AUTOSAR XML (schema 4-2-1)
# Copyright (c) 2018 Vector Informatik GmbH.
# License is restricted to the usage with CBD1800851 (D01) for MSR_Ford_SLP1.
# Please contact Vector Informatik whenever you need further information concerning the license conditions.
standard types defined: boolean, sint8, uint16, uint32, uint8
package /VehicleProject
  system System
package /Cluster
  can cluster CAN00: protocol-name=CAN  # PlatformDBCE4v7
    can physical channel CHNL: comm-connectors=CN_CAN00
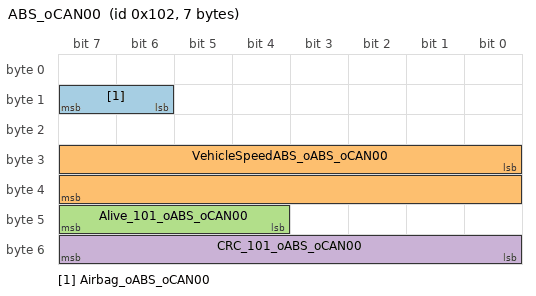
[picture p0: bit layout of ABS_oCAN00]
      frame ABS_oCAN00: id 0x102, to IC, frame-length=7, can-addressing-mode=STANDARD
        pdu ABS_oCAN00: length=7, minimum-delay=0, transmission-mode-false-timing=cyclic-timing={time-offset=0, time-period=0.1}, transmission-mode-true-timing=cyclic-timing={time-offset=0, time-period=0.1}, unused-bit-pattern=0
          signal Airbag_oABS_oCAN00: start 14, 2 bit, little-endian, init-value=0, base-type=uint8, compu {0=Cx0_Off, 1=Cx1_On, 2=Cx2_Blink, 3=Cx3_Reserved}, transfer-property=PENDING, to IC
          signal VehicleSpeedABS_oABS_oCAN00: start 24, 16 bit, little-endian, init-value=0, base-type=uint16, compu {phys=raw*0.0625 for raw 0..4800; unit kmph}, unit=kmph, transfer-property=PENDING, to IC
          signal Alive_101_oABS_oCAN00: start 44, 4 bit, little-endian, init-value=0, base-type=uint8, compu {identical}, range raw 0..15, transfer-property=PENDING, to IC
          signal CRC_101_oABS_oCAN00: start 48, 8 bit, little-endian, init-value=0, base-type=uint8, compu {identical}, range raw 0..255, transfer-property=PENDING, to IC
          mapping SG_ABS: i-signal-group=SG_ABS_oABS_oCAN00, transfer-property=PENDING
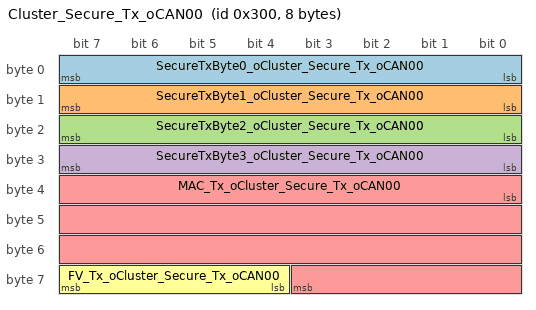
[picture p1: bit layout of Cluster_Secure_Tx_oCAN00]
      frame Cluster_Secure_Tx_oCAN00: id 0x300, from IC, frame-length=8, can-addressing-mode=STANDARD
        pdu Cluster_Secure_Tx_oCAN00: length=8, minimum-delay=0, transmission-mode-false-timing=cyclic-timing={time-offset=0, time-period=0}, transmission-mode-true-timing=cyclic-timing={time-offset=0, time-period=0}, unused-bit-pattern=0
          signal SecureTxByte0_oCluster_Secure_Tx_oCAN00: start 0, 8 bit, little-endian, init-value=0, base-type=uint8, compu {identical}, range raw 0..255, transfer-property=PENDING
          signal SecureTxByte1_oCluster_Secure_Tx_oCAN00: start 8, 8 bit, little-endian, init-value=0, base-type=uint8, compu {identical}, range raw 0..255, transfer-property=PENDING
          signal SecureTxByte2_oCluster_Secure_Tx_oCAN00: start 16, 8 bit, little-endian, init-value=0, base-type=uint8, compu {identical}, range raw 0..255, transfer-property=PENDING
          signal SecureTxByte3_oCluster_Secure_Tx_oCAN00: start 24, 8 bit, little-endian, init-value=0, base-type=uint8, compu {identical}, range raw 0..255, transfer-property=PENDING
          signal MAC_Tx_oCluster_Secure_Tx_oCAN00: start 32, 28 bit, little-endian, init-value=0, base-type=uint32, compu {identical}, range raw 0..268435455, transfer-property=PENDING  # 28 bit CMAC/HMAC for securing the message
          signal FV_Tx_oCluster_Secure_Tx_oCAN00: start 60, 4 bit, little-endian, init-value=0, base-type=uint8, compu {identical}, range raw 0..15, unit=No Unit, transfer-property=PENDING
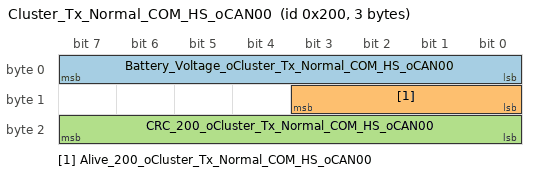
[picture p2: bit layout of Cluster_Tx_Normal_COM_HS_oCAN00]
      frame Cluster_Tx_Normal_COM_HS_oCAN00: id 0x200, from IC, frame-length=3, can-addressing-mode=STANDARD
        pdu Cluster_Tx_Normal_COM_HS_oCAN00: length=3, minimum-delay=0, transmission-mode-false-timing=cyclic-timing={time-offset=0, time-period=0.01}, transmission-mode-true-timing=cyclic-timing={time-offset=0, time-period=0.01}, unused-bit-pattern=0
          signal Battery_Voltage_oCluster_Tx_Normal_COM_HS_oCAN00: start 0, 8 bit, little-endian, init-value=0, base-type=uint8, compu {phys=raw*0.25 for raw 0..255; unit V}, unit=V, transfer-property=PENDING
          signal Alive_200_oCluster_Tx_Normal_COM_HS_oCAN00: start 8, 4 bit, little-endian, init-value=0, base-type=uint8, compu {identical}, range raw 0..15, transfer-property=PENDING
          signal CRC_200_oCluster_Tx_Normal_COM_HS_oCAN00: start 16, 8 bit, little-endian, init-value=0, base-type=uint8, compu {identical}, range raw 0..255, transfer-property=PENDING
          mapping SG_COM_HS: i-signal-group=SG_COM_HS_oCluster_Tx_Normal_COM_HS_oCAN00, transfer-property=PENDING
      frame Cluster_Tx_Normal_COM_LS_oCAN00: id 0x202, from IC, frame-length=4, can-addressing-mode=STANDARD
        pdu Cluster_Tx_Normal_COM_LS_oCAN00: length=4, minimum-delay=0, transmission-mode-false-timing=cyclic-timing={time-offset=0, time-period=1}, transmission-mode-true-timing=cyclic-timing={time-offset=0, time-period=1}, unused-bit-pattern=0
          signal Odometer_oCluster_Tx_Normal_COM_LS_oCAN00: start 0, 32 bit, little-endian, init-value=0, base-type=uint32, compu {identical}, range raw 0..1609343, unit=km, transfer-property=PENDING
      frame Cluster_Tx_Normal_COM_MS_oCAN00: id 0x201, from IC, frame-length=2, can-addressing-mode=STANDARD
        pdu Cluster_Tx_Normal_COM_MS_oCAN00: length=2, minimum-delay=0, transmission-mode-false-timing=cyclic-timing={time-offset=0, time-period=0.1}, transmission-mode-true-timing=cyclic-timing={time-offset=0, time-period=0.1}, unused-bit-pattern=0
          signal VehicleSpeedIC_oCluster_Tx_Normal_COM_MS_oCAN00: start 0, 16 bit, little-endian, init-value=0, base-type=uint16, compu {phys=raw*0.0625 for raw 0..4800; unit kmph}, unit=kmph, transfer-property=PENDING
      frame Cluster_Tx_Reduced_Com_oCAN00: id 0x210, from IC, frame-length=1, can-addressing-mode=STANDARD  # to be transmitted in reduced comm state as well
        pdu Cluster_Tx_Reduced_Com_oCAN00: length=1, minimum-delay=0, transmission-mode-false-timing=cyclic-timing={time-offset=0, time-period=0.1}, transmission-mode-true-timing=cyclic-timing={time-offset=0, time-period=0.1}, unused-bit-pattern=0
          signal Illumination_PWM_oCluster_Tx_Reduced_Com_oCAN00: start 0, 8 bit, little-endian, init-value=0, base-type=uint8, compu {identical}, range raw 0..100, unit=%, transfer-property=PENDING
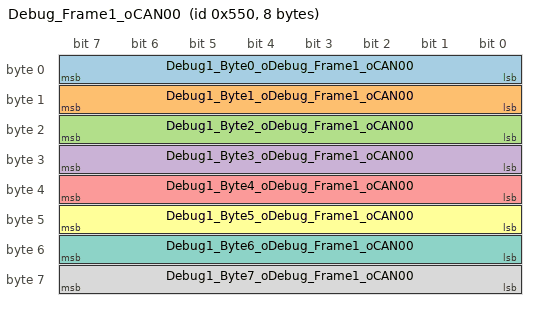
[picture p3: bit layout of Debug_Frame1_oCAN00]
      frame Debug_Frame1_oCAN00: id 0x550, from IC, frame-length=8, can-addressing-mode=STANDARD
        pdu Debug_Frame1_oCAN00: length=8, minimum-delay=0, transmission-mode-false-timing=cyclic-timing={time-offset=0, time-period=0.01}, transmission-mode-true-timing=cyclic-timing={time-offset=0, time-period=0.01}, unused-bit-pattern=0
          signal Debug1_Byte0_oDebug_Frame1_oCAN00: start 0, 8 bit, little-endian, init-value=0, base-type=uint8, compu {identical}, range raw 0..255, transfer-property=PENDING
          signal Debug1_Byte1_oDebug_Frame1_oCAN00: start 8, 8 bit, little-endian, init-value=0, base-type=uint8, compu {identical}, range raw 0..255, transfer-property=PENDING
          signal Debug1_Byte2_oDebug_Frame1_oCAN00: start 16, 8 bit, little-endian, init-value=0, base-type=uint8, compu {identical}, range raw 0..255, transfer-property=PENDING
          signal Debug1_Byte3_oDebug_Frame1_oCAN00: start 24, 8 bit, little-endian, init-value=0, base-type=uint8, compu {identical}, range raw 0..255, transfer-property=PENDING
          signal Debug1_Byte4_oDebug_Frame1_oCAN00: start 32, 8 bit, little-endian, init-value=0, base-type=uint8, compu {identical}, range raw 0..255, transfer-property=PENDING
          signal Debug1_Byte5_oDebug_Frame1_oCAN00: start 40, 8 bit, little-endian, init-value=0, base-type=uint8, compu {identical}, range raw 0..255, transfer-property=PENDING
          signal Debug1_Byte6_oDebug_Frame1_oCAN00: start 48, 8 bit, little-endian, init-value=0, base-type=uint8, compu {identical}, range raw 0..255, transfer-property=PENDING
          signal Debug1_Byte7_oDebug_Frame1_oCAN00: start 56, 8 bit, little-endian, init-value=0, base-type=uint8, compu {identical}, range raw 0..255, transfer-property=PENDING
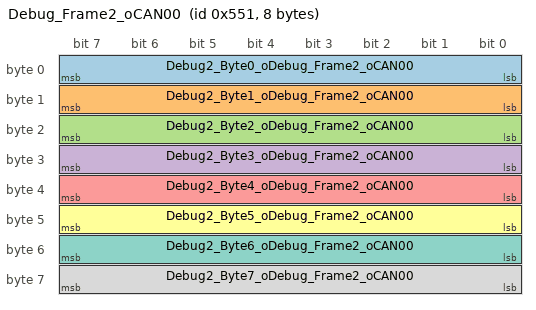
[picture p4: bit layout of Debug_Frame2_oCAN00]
      frame Debug_Frame2_oCAN00: id 0x551, from IC, frame-length=8, can-addressing-mode=STANDARD
        pdu Debug_Frame2_oCAN00: length=8, minimum-delay=0, transmission-mode-false-timing=cyclic-timing={time-offset=0, time-period=0.1}, transmission-mode-true-timing=cyclic-timing={time-offset=0, time-period=0.1}, unused-bit-pattern=0
          signal Debug2_Byte0_oDebug_Frame2_oCAN00: start 0, 8 bit, little-endian, init-value=0, base-type=uint8, compu {identical}, range raw 0..255, transfer-property=PENDING
          signal Debug2_Byte1_oDebug_Frame2_oCAN00: start 8, 8 bit, little-endian, init-value=0, base-type=uint8, compu {identical}, range raw 0..255, transfer-property=PENDING
          signal Debug2_Byte2_oDebug_Frame2_oCAN00: start 16, 8 bit, little-endian, init-value=0, base-type=uint8, compu {identical}, range raw 0..255, transfer-property=PENDING
          signal Debug2_Byte3_oDebug_Frame2_oCAN00: start 24, 8 bit, little-endian, init-value=0, base-type=uint8, compu {identical}, range raw 0..255, transfer-property=PENDING
          signal Debug2_Byte4_oDebug_Frame2_oCAN00: start 32, 8 bit, little-endian, init-value=0, base-type=uint8, compu {identical}, range raw 0..255, transfer-property=PENDING
          signal Debug2_Byte5_oDebug_Frame2_oCAN00: start 40, 8 bit, little-endian, init-value=0, base-type=uint8, compu {identical}, range raw 0..255, transfer-property=PENDING
          signal Debug2_Byte6_oDebug_Frame2_oCAN00: start 48, 8 bit, little-endian, init-value=0, base-type=uint8, compu {identical}, range raw 0..255, transfer-property=PENDING
          signal Debug2_Byte7_oDebug_Frame2_oCAN00: start 56, 8 bit, little-endian, init-value=0, base-type=uint8, compu {identical}, range raw 0..255, transfer-property=PENDING
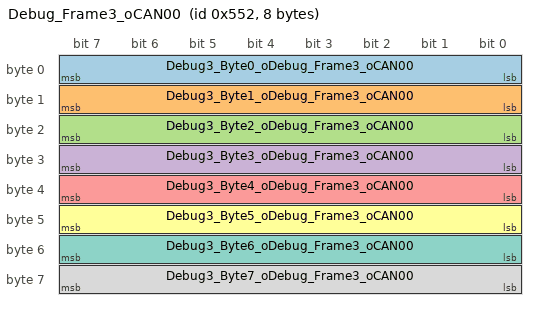
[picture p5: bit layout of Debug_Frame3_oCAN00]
      frame Debug_Frame3_oCAN00: id 0x552, from IC, frame-length=8, can-addressing-mode=STANDARD
        pdu Debug_Frame3_oCAN00: length=8, minimum-delay=0, transmission-mode-false-timing=cyclic-timing={time-offset=0, time-period=0.1}, transmission-mode-true-timing=cyclic-timing={time-offset=0, time-period=0.1}, unused-bit-pattern=0
          signal Debug3_Byte0_oDebug_Frame3_oCAN00: start 0, 8 bit, little-endian, init-value=0, base-type=uint8, compu {identical}, range raw 0..255, transfer-property=PENDING
          signal Debug3_Byte1_oDebug_Frame3_oCAN00: start 8, 8 bit, little-endian, init-value=0, base-type=uint8, compu {identical}, range raw 0..255, transfer-property=PENDING
          signal Debug3_Byte2_oDebug_Frame3_oCAN00: start 16, 8 bit, little-endian, init-value=0, base-type=uint8, compu {identical}, range raw 0..255, transfer-property=PENDING
          signal Debug3_Byte3_oDebug_Frame3_oCAN00: start 24, 8 bit, little-endian, init-value=0, base-type=uint8, compu {identical}, range raw 0..255, transfer-property=PENDING
          signal Debug3_Byte4_oDebug_Frame3_oCAN00: start 32, 8 bit, little-endian, init-value=0, base-type=uint8, compu {identical}, range raw 0..255, transfer-property=PENDING
          signal Debug3_Byte5_oDebug_Frame3_oCAN00: start 40, 8 bit, little-endian, init-value=0, base-type=uint8, compu {identical}, range raw 0..255, transfer-property=PENDING
          signal Debug3_Byte6_oDebug_Frame3_oCAN00: start 48, 8 bit, little-endian, init-value=0, base-type=uint8, compu {identical}, range raw 0..255, transfer-property=PENDING
          signal Debug3_Byte7_oDebug_Frame3_oCAN00: start 56, 8 bit, little-endian, init-value=0, base-type=uint8, compu {identical}, range raw 0..255, transfer-property=PENDING
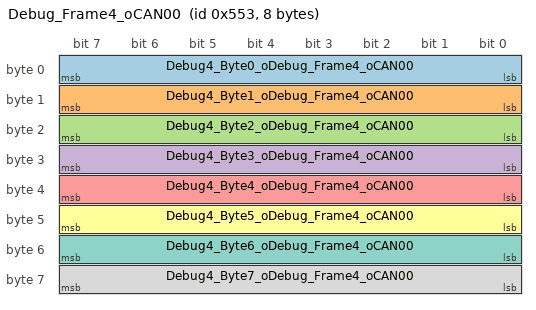
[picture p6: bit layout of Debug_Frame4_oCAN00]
      frame Debug_Frame4_oCAN00: id 0x553, from IC, frame-length=8, can-addressing-mode=STANDARD
        pdu Debug_Frame4_oCAN00: length=8, minimum-delay=0, transmission-mode-false-timing=cyclic-timing={time-offset=0, time-period=0.1}, transmission-mode-true-timing=cyclic-timing={time-offset=0, time-period=0.1}, unused-bit-pattern=0
          signal Debug4_Byte0_oDebug_Frame4_oCAN00: start 0, 8 bit, little-endian, init-value=0, base-type=uint8, compu {identical}, range raw 0..255, transfer-property=PENDING
          signal Debug4_Byte1_oDebug_Frame4_oCAN00: start 8, 8 bit, little-endian, init-value=0, base-type=uint8, compu {identical}, range raw 0..255, transfer-property=PENDING
          signal Debug4_Byte2_oDebug_Frame4_oCAN00: start 16, 8 bit, little-endian, init-value=0, base-type=uint8, compu {identical}, range raw 0..255, transfer-property=PENDING
          signal Debug4_Byte3_oDebug_Frame4_oCAN00: start 24, 8 bit, little-endian, init-value=0, base-type=uint8, compu {identical}, range raw 0..255, transfer-property=PENDING
          signal Debug4_Byte4_oDebug_Frame4_oCAN00: start 32, 8 bit, little-endian, init-value=0, base-type=uint8, compu {identical}, range raw 0..255, transfer-property=PENDING
          signal Debug4_Byte5_oDebug_Frame4_oCAN00: start 40, 8 bit, little-endian, init-value=0, base-type=uint8, compu {identical}, range raw 0..255, transfer-property=PENDING
          signal Debug4_Byte6_oDebug_Frame4_oCAN00: start 48, 8 bit, little-endian, init-value=0, base-type=uint8, compu {identical}, range raw 0..255, transfer-property=PENDING
          signal Debug4_Byte7_oDebug_Frame4_oCAN00: start 56, 8 bit, little-endian, init-value=0, base-type=uint8, compu {identical}, range raw 0..255, transfer-property=PENDING
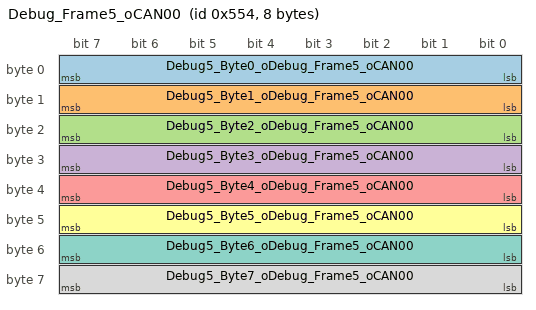
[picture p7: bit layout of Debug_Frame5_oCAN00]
      frame Debug_Frame5_oCAN00: id 0x554, from IC, frame-length=8, can-addressing-mode=STANDARD
        pdu Debug_Frame5_oCAN00: length=8, minimum-delay=0, transmission-mode-false-timing=cyclic-timing={time-offset=0, time-period=0}, transmission-mode-true-timing=cyclic-timing={time-offset=0, time-period=0}, unused-bit-pattern=0
          signal Debug5_Byte0_oDebug_Frame5_oCAN00: start 0, 8 bit, little-endian, init-value=0, base-type=uint8, compu {identical}, range raw 0..255, transfer-property=PENDING
          signal Debug5_Byte1_oDebug_Frame5_oCAN00: start 8, 8 bit, little-endian, init-value=0, base-type=uint8, compu {identical}, range raw 0..255, transfer-property=PENDING
          signal Debug5_Byte2_oDebug_Frame5_oCAN00: start 16, 8 bit, little-endian, init-value=0, base-type=uint8, compu {identical}, range raw 0..255, transfer-property=PENDING
          signal Debug5_Byte3_oDebug_Frame5_oCAN00: start 24, 8 bit, little-endian, init-value=0, base-type=uint8, compu {identical}, range raw 0..255, transfer-property=PENDING
          signal Debug5_Byte4_oDebug_Frame5_oCAN00: start 32, 8 bit, little-endian, init-value=0, base-type=uint8, compu {identical}, range raw 0..255, transfer-property=PENDING
          signal Debug5_Byte5_oDebug_Frame5_oCAN00: start 40, 8 bit, little-endian, init-value=0, base-type=uint8, compu {identical}, range raw 0..255, transfer-property=PENDING
          signal Debug5_Byte6_oDebug_Frame5_oCAN00: start 48, 8 bit, little-endian, init-value=0, base-type=uint8, compu {identical}, range raw 0..255, transfer-property=PENDING
          signal Debug5_Byte7_oDebug_Frame5_oCAN00: start 56, 8 bit, little-endian, init-value=0, base-type=uint8, compu {identical}, range raw 0..255, transfer-property=PENDING
      frame Diag_Resp_USDT_oCAN00: id 0x708, from IC, frame-length=8, can-addressing-mode=STANDARD
        pdu Diag_Resp_USDT_oCAN00: length=8, minimum-delay=0, transmission-mode-false-timing=cyclic-timing={time-offset=0, time-period=0}, transmission-mode-true-timing=cyclic-timing={time-offset=0, time-period=0}, unused-bit-pattern=0
          signal Diag_Buffer_Tx_USDT_oDiag_Resp_USDT_oCAN00: start 0, 64 bit, opaque, init-value=8 x 0, base-type=uint8_8_iso_8859_1, compu {identical}, range raw 0..18446744073709551615, transfer-property=PENDING
      frame Diag_Resp_UUDT_oCAN00: id 0x608, from IC, frame-length=8, can-addressing-mode=STANDARD
        pdu Diag_Resp_UUDT_oCAN00: length=8, minimum-delay=0, transmission-mode-false-timing=cyclic-timing={time-offset=0, time-period=0}, transmission-mode-true-timing=cyclic-timing={time-offset=0, time-period=0}, unused-bit-pattern=0
          signal Diag_Buffer_Tx_UUDT_oDiag_Resp_UUDT_oCAN00: start 0, 64 bit, opaque, init-value=8 x 0, base-type=uint8_8_iso_8859_1, compu {identical}, range raw 0..18446744073709551615, transfer-property=PENDING
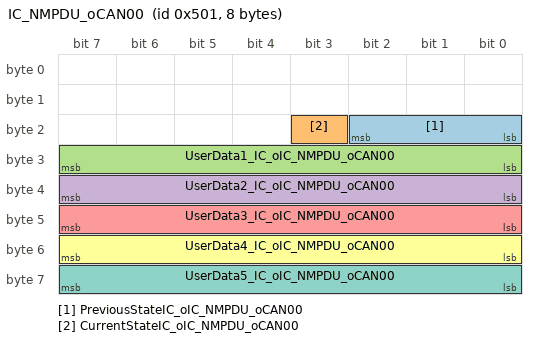
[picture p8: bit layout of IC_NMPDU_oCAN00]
      frame IC_NMPDU_oCAN00: id 0x501, from IC, frame-length=8, can-addressing-mode=STANDARD
        nm pdu IC_NMPDU_oCAN00: length=8, unused-bit-pattern=0
          signal PreviousStateIC_oIC_NMPDU_oCAN00: start 16, 3 bit, little-endian, init-value=0, base-type=sint8, compu {identical}, range raw -4..3, transfer-property=PENDING
          signal CurrentStateIC_oIC_NMPDU_oCAN00: start 19, 1 bit, little-endian, init-value=0, base-type=boolean, compu {identical}, range raw -1..0, transfer-property=PENDING
          signal UserData1_IC_oIC_NMPDU_oCAN00: start 24, 8 bit, little-endian, init-value=0, base-type=uint8, compu {identical}, range raw 0..255, transfer-property=PENDING
          signal UserData2_IC_oIC_NMPDU_oCAN00: start 32, 8 bit, little-endian, init-value=0, base-type=uint8, compu {identical}, range raw 0..255, transfer-property=PENDING
          signal UserData3_IC_oIC_NMPDU_oCAN00: start 40, 8 bit, little-endian, init-value=0, base-type=uint8, compu {identical}, range raw 0..255, transfer-property=PENDING
          signal UserData4_IC_oIC_NMPDU_oCAN00: start 48, 8 bit, little-endian, init-value=0, base-type=uint8, compu {identical}, range raw 0..255, transfer-property=PENDING
          signal UserData5_IC_oIC_NMPDU_oCAN00: start 56, 8 bit, little-endian, init-value=0, base-type=uint8, compu {identical}, range raw 0..255, transfer-property=PENDING
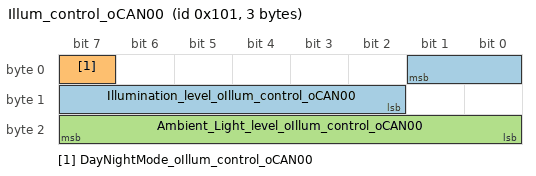
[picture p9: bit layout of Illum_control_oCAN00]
      frame Illum_control_oCAN00: id 0x101, to IC, frame-length=3, can-addressing-mode=STANDARD
        pdu Illum_control_oCAN00: length=3, minimum-delay=0, transmission-mode-false-timing=cyclic-timing={time-offset=0, time-period=0.1}, transmission-mode-true-timing=cyclic-timing={time-offset=0, time-period=0.1}, unused-bit-pattern=0
          signal Illumination_level_oIllum_control_oCAN00: start 1, 8 bit, big-endian, init-value=0, base-type=uint8, compu {identical}, range raw 0..255, unit=%, transfer-property=PENDING, to IC
          signal DayNightMode_oIllum_control_oCAN00: start 7, 1 bit, big-endian, init-value=0, base-type=boolean, compu {0=Cx0_Day, 1=Cx1_Night}, transfer-property=PENDING, to IC
          signal Ambient_Light_level_oIllum_control_oCAN00: start 23, 8 bit, big-endian, init-value=0, base-type=uint8, compu {identical}, range raw 0..100, unit=%, transfer-property=PENDING, to IC
      frame NM_CoOrd_NMPDU_oCAN00: id 0x500, to IC, frame-length=8, can-addressing-mode=STANDARD
        nm pdu NM_CoOrd_NMPDU_oCAN00: length=8, unused-bit-pattern=0
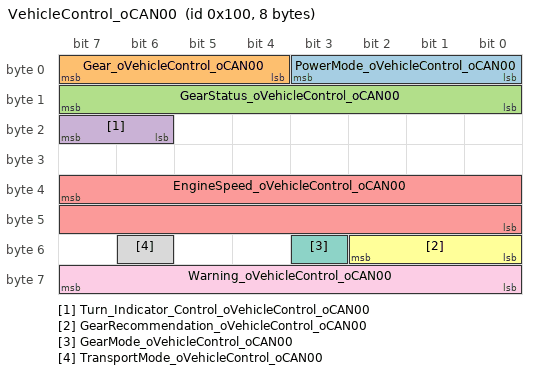
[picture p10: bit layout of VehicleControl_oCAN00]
      frame VehicleControl_oCAN00: id 0x100, to IC, frame-length=8, can-addressing-mode=STANDARD
        pdu VehicleControl_oCAN00: length=8, minimum-delay=0, transmission-mode-false-timing=cyclic-timing={time-offset=0, time-period=0.01}, transmission-mode-true-timing=cyclic-timing={time-offset=0, time-period=0.01}, unused-bit-pattern=0
          signal PowerMode_oVehicleControl_oCAN00: start 0, 4 bit, little-endian, init-value=0, base-type=uint8, compu {0=Cx0_Off, 1=Cx1_Awake, 2=Cx2_Accessory, 3=Cx3_Ignition_On (Ignition On), 4=Cx4_Run_Engine_or_Motor_on_ (Run(Engine_or_Motor_on))}, transfer-property=PENDING, to IC
          signal Gear_oVehicleControl_oCAN00: start 7, 4 bit, big-endian, init-value=0, base-type=uint8, compu {identical}, range raw 0..15, transfer-property=PENDING, to IC
          signal GearStatus_oVehicleControl_oCAN00: start 15, 8 bit, big-endian, init-value=0, base-type=uint8, compu {0=Cx00_On, 1=Cx01_Blink}, transfer-property=PENDING, to IC
          signal Turn_Indicator_Control_oVehicleControl_oCAN00: start 22, 2 bit, little-endian, init-value=0, base-type=uint8, compu {identical}, range raw 0..3, transfer-property=PENDING, to IC
          signal EngineSpeed_oVehicleControl_oCAN00: start 39, 16 bit, big-endian, init-value=0, base-type=uint16, compu {phys=raw*0.78125 for raw 0..65535}, transfer-property=PENDING, to IC
          signal GearRecommendation_oVehicleControl_oCAN00: start 50, 3 bit, big-endian, init-value=0, base-type=uint8, compu {0=Cx0_No_Indication (No Indication), 1=Cx1_GearUp, 2=Cx2_GearDown, 3=Cx3_GearUpBlink, 4=Cx4_GearDownBlinkl, 5=Cx5_Reserved, 6=Cx6_Reserved, 7=Cx7_Reserved}, transfer-property=PENDING, to IC
          signal GearMode_oVehicleControl_oCAN00: start 51, 1 bit, big-endian, init-value=0, base-type=boolean, compu {0=Cx0_Manual, 1=Cx1_Auto}, transfer-property=PENDING, to IC
          signal TransportMode_oVehicleControl_oCAN00: start 54, 1 bit, little-endian, init-value=0, base-type=boolean, compu {0=Cx0_Transport_Link_Off (Transport Link Off), 1=Cx1_Transport_Link_Active (Transport Link Active)}, transfer-property=PENDING, to IC  # This signal is used to enable/disable tranpsort mode
          signal Warning_oVehicleControl_oCAN00: start 63, 8 bit, big-endian, init-value=0, base-type=uint8, compu {identical}, range raw 0..255, transfer-property=PENDING, to IC  # a generic warning input, Map values to specific warnings
package /ECU
  ecu instance IC: associated-com-i-pdu-group=[IC_oCAN00_Rx, IC_oCAN00_Tx]
    can communication controller CT_CAN00
    can communication connector CN_CAN00: comm-controller=CT_CAN00
package /IPDUGroup
  i signal i pdu group IC_oCAN00_Rx: communication-direction=IN, i-signal-i-pdus=[ABS_oCAN00, Illum_control_oCAN00, VehicleControl_oCAN00]
  i signal i pdu group IC_oCAN00_Tx: communication-direction=OUT
    i-signal-i-pdus:
      Cluster_Secure_Tx_oCAN00
      Cluster_Tx_Normal_COM_HS_oCAN00
      Cluster_Tx_Normal_COM_LS_oCAN00
      Cluster_Tx_Normal_COM_MS_oCAN00
      Cluster_Tx_Reduced_Com_oCAN00
      Debug_Frame{1..5}_oCAN00
      Diag_Resp_USDT_oCAN00
      Diag_Resp_UUDT_oCAN00
package /ISignal
  i signal group SG_ABS_oABS_oCAN00: i-signal=[Airbag_oABS_oCAN00, Alive_101_oABS_oCAN00, CRC_101_oABS_oCAN00, VehicleSpeedABS_oABS_oCAN00], system-signal-group=SG_ABS
  i signal group SG_COM_HS_oCluster_Tx_Normal_COM_HS_oCAN00: i-signal=[Alive_200_oCluster_Tx_Normal_COM_HS_oCAN00, Battery_Voltage_oCluster_Tx_Normal_COM_HS_oCAN00, CRC_200_oCluster_Tx_Normal_COM_HS_oCAN00], system-signal-group=SG_COM_HS
package /DataType
  base type uint8_8_iso_8859_1: category=FIXED_LENGTH, base-type-size=64, base-type-encoding=ISO-8859-1
package /DataType/Unit
  5 x unit:
    U_km: display-name=km
    U_kmph: display-name=kmph
    U_No_Unit: display-name=No Unit
    U_p: display-name=%
    U_V: display-name=V
